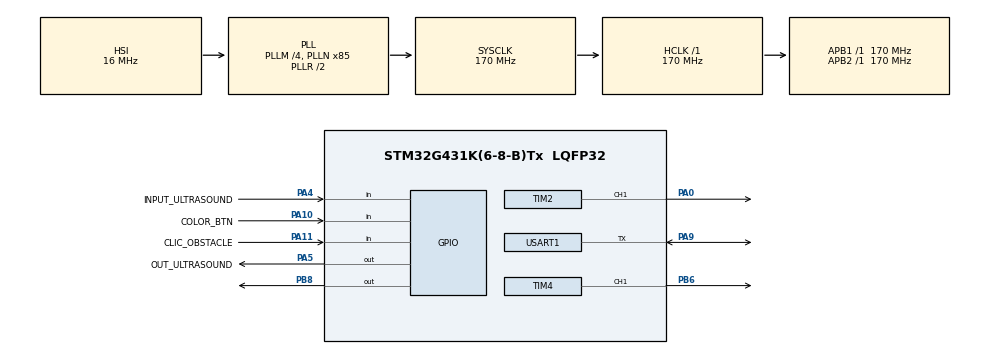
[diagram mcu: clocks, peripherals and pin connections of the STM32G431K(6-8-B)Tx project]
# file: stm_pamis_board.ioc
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Mcu.Family=STM32G4
Mcu.Name=STM32G431K(6-8-B)Tx
Mcu.Package=LQFP32
NUCLEO-G431KB.LD2=true
NUCLEO-G431KB.VCP=true
NVIC.PriorityGroup=NVIC_PRIORITYGROUP_4
PA0.Signal=S_TIM2_CH1
PA10.GPIO_Label=COLOR_BTN
PA10.GPIO_PuPd=GPIO_PULLUP
PA10.Signal=GPIO_Input
PA11.GPIO_Label=CLIC_OBSTACLE
PA11.GPIO_PuPd=GPIO_PULLUP
PA11.Signal=GPIO_Input
PA13.GPIO_Label=T_SWDIO
PA13.Signal=SYS_JTMS-SWDIO
PA14.GPIO_Label=T_SWCLK
PA14.Signal=SYS_JTCK-SWCLK
PA2.Signal=USART2_TX
PA3.Signal=USART2_RX
PA4.GPIO_Label=INPUT_ULTRASOUND
PA4.Signal=GPIO_Input
PA5.GPIO_Label=OUT_ULTRASOUND
PA5.Signal=GPIO_Output
PA9.GPIO_Speed=GPIO_SPEED_FREQ_VERY_HIGH
PA9.Mode=Half_duplex(single_wire_mode)
PA9.Signal=USART1_TX
PB3.GPIO_Label=T_SWO
PB3.Signal=SYS_JTDO-SWO
PB6.Signal=S_TIM4_CH1
PB8-BOOT0.Signal=GPIO_Output
ProjectManager.HeapSize=0x200
ProjectManager.StackSize=0x400
ProjectManager.TargetToolchain=STM32CubeIDE
RCC.ADC12Freq_Value=170000000
RCC.AHBFreq_Value=170000000
RCC.APB1Freq_Value=170000000
RCC.APB1TimFreq_Value=170000000
RCC.APB2Freq_Value=170000000
RCC.APB2TimFreq_Value=170000000
RCC.CortexFreq_Value=170000000
RCC.EXTERNAL_CLOCK_VALUE=12288000
RCC.HCLKFreq_Value=170000000
RCC.HSE_VALUE=8000000
RCC.HSI48_VALUE=48000000
RCC.HSI_VALUE=16000000
RCC.LSE_VALUE=32768
RCC.PLLM=RCC_PLLM_DIV4
RCC.PLLN=85
RCC.SYSCLKFreq_VALUE=170000000
RCC.SYSCLKSource=RCC_SYSCLKSOURCE_PLLCLK
RCC.USBFreq_Value=170000000
RCC.VCOOutputFreq_Value=340000000
SH.S_TIM2_CH1.0=TIM2_CH1,PWM Generation1 CH1
SH.S_TIM4_CH1.0=TIM4_CH1,PWM Generation1 CH1
TIM1.Prescaler=71
TIM2.Channel-PWM\ Generation1\ CH1=TIM_CHANNEL_1
TIM2.PeriodNoDither=1000-1
TIM2.Prescaler=1440-1
TIM4.Channel-PWM\ Generation1\ CH1=TIM_CHANNEL_1
TIM4.PeriodNoDither=255
USART1.BaudRate=1000000
USART1.VirtualMode-Half_duplex(single_wire_mode)=VM_ASYNC
VP_NUCLEO-G431KB_VS_BSP_COMMON.Mode=COMMON
VP_SYS_VS_DBSignals.Mode=DisableDeadBatterySignals
VP_TIM1_VS_ClockSourceINT.Mode=Internal
VP_TIM2_VS_ClockSourceINT.Mode=Internal
VP_TIM4_VS_ClockSourceINT.Mode=Internal
board=NUCLEO-G431KB

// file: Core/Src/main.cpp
/* USER CODE BEGIN Header */
/**
  ******************************************************************************
  * @file           : main.c
  * @brief          : Main program body
  ******************************************************************************
  * @attention
  *
  * Copyright (c) 2025 STMicroelectronics.
  * All rights reserved.
  *
  * This software is licensed under terms that can be found in the LICENSE file
  * in the root directory of this software component.
  * If no LICENSE file comes with this software, it is provided AS-IS.
  *
  ******************************************************************************
  */
/* USER CODE END Header */
#include "main.h"
#include "tim.h"
#include "usart.h"
#include "gpio.h"

/* USER CODE BEGIN Includes */
#include "pami.h"

/* USER CODE END Includes */

COM_InitTypeDef BspCOMInit;

void SystemClock_Config(void);

int main(void)
{

  /* MCU Configuration--------------------------------------------------------*/

  /* Reset of all peripherals, Initializes the Flash interface and the Systick. */
  HAL_Init();

  /* Configure the system clock */
  SystemClock_Config();

  /* Initialize all configured peripherals */
  MX_GPIO_Init();
  MX_USART1_UART_Init();
  MX_TIM2_Init();
  MX_TIM4_Init();
  MX_TIM1_Init();

  /* Initialize leds */
  BSP_LED_Init(LED_GREEN);

  /* Initialize COM1 port (115200, 8 bits (7-bit data + 1 stop bit), no parity */
  BspCOMInit.BaudRate   = 115200;
  BspCOMInit.WordLength = COM_WORDLENGTH_8B;
  BspCOMInit.StopBits   = COM_STOPBITS_1;
  BspCOMInit.Parity     = COM_PARITY_NONE;
  BspCOMInit.HwFlowCtl  = COM_HWCONTROL_NONE;
  if (BSP_COM_Init(COM1, &BspCOMInit) != BSP_ERROR_NONE)
  {
    Error_Handler();
  }

  /* Infinite loop */
  /* USER CODE BEGIN WHILE */

  PAMI_Init();
  PAMI_Main();

  while (1)
  {
    HAL_Delay(1000);

    /* USER CODE END WHILE */

  }
}

void SystemClock_Config(void)
{
  RCC_OscInitTypeDef RCC_OscInitStruct = {0};
  RCC_ClkInitTypeDef RCC_ClkInitStruct = {0};

  /** Configure the main internal regulator output voltage
  */
  HAL_PWREx_ControlVoltageScaling(PWR_REGULATOR_VOLTAGE_SCALE1_BOOST);

  /** Initializes the RCC Oscillators according to the specified parameters
  * in the RCC_OscInitTypeDef structure.
  */
  RCC_OscInitStruct.OscillatorType = RCC_OSCILLATORTYPE_HSI;
  RCC_OscInitStruct.HSIState = RCC_HSI_ON;
  RCC_OscInitStruct.HSICalibrationValue = RCC_HSICALIBRATION_DEFAULT;
  RCC_OscInitStruct.PLL.PLLState = RCC_PLL_ON;
  RCC_OscInitStruct.PLL.PLLSource = RCC_PLLSOURCE_HSI;
  RCC_OscInitStruct.PLL.PLLM = RCC_PLLM_DIV4;
  RCC_OscInitStruct.PLL.PLLN = 85;
  RCC_OscInitStruct.PLL.PLLP = RCC_PLLP_DIV2;
  RCC_OscInitStruct.PLL.PLLQ = RCC_PLLQ_DIV2;
  RCC_OscInitStruct.PLL.PLLR = RCC_PLLR_DIV2;
  if (HAL_RCC_OscConfig(&RCC_OscInitStruct) != HAL_OK)
  {
    Error_Handler();
  }

  /** Initializes the CPU, AHB and APB buses clocks
  */
  RCC_ClkInitStruct.ClockType = RCC_CLOCKTYPE_HCLK|RCC_CLOCKTYPE_SYSCLK
                              |RCC_CLOCKTYPE_PCLK1|RCC_CLOCKTYPE_PCLK2;
  RCC_ClkInitStruct.SYSCLKSource = RCC_SYSCLKSOURCE_PLLCLK;
  RCC_ClkInitStruct.AHBCLKDivider = RCC_SYSCLK_DIV1;
  RCC_ClkInitStruct.APB1CLKDivider = RCC_HCLK_DIV1;
  RCC_ClkInitStruct.APB2CLKDivider = RCC_HCLK_DIV1;

  if (HAL_RCC_ClockConfig(&RCC_ClkInitStruct, FLASH_LATENCY_4) != HAL_OK)
  {
    Error_Handler();
  }
}

/* USER CODE BEGIN Header */
/**
  ******************************************************************************
  * @file           : main.c
  * @brief          : Main program body
  ******************************************************************************
  * @attention
  *
  * Copyright (c) 2025 STMicroelectronics.
  * All rights reserved.
  *
  * This software is licensed under terms that can be found in the LICENSE file
  * in the root directory of this software component.
  * If no LICENSE file comes with this software, it is provided AS-IS.
  *
  ******************************************************************************
  */
/* USER CODE END Header */

void Error_Handler(void)
{
  __disable_irq();
  while (1)
  {
  }
}
